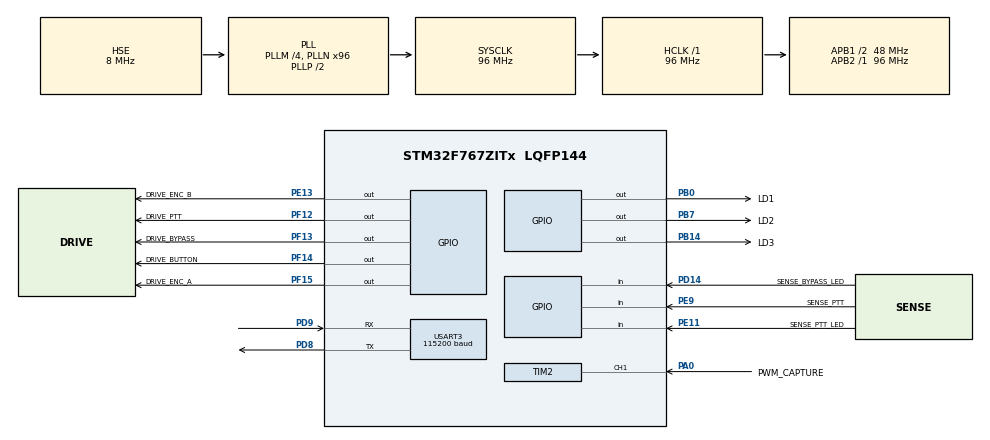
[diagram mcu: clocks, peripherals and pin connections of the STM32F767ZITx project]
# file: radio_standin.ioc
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IWDG.Prescaler=IWDG_PRESCALER_32
IWDG.Reload=1999
Mcu.Family=STM32F7
Mcu.Name=STM32F767ZITx
Mcu.Package=LQFP144
NVIC.PriorityGroup=NVIC_PRIORITYGROUP_4
NVIC.TIM2_IRQn=true\:1\:0\:false\:false\:true\:true\:true\:true
NVIC.USART3_IRQn=true\:2\:0\:false\:false\:true\:true\:true\:true
PA0/WKUP.GPIO_Label=PWM_CAPTURE
PA0/WKUP.Signal=S_TIM2_CH1_ETR
PA13.Signal=SYS_JTMS-SWDIO
PA14.Signal=SYS_JTCK-SWCLK
PB0.GPIO_Label=LD1
PB0.Signal=GPIO_Output
PB14.GPIO_Label=LD3
PB14.Signal=GPIO_Output
PB7.GPIO_Label=LD2
PB7.Signal=GPIO_Output
PD14.GPIO_Label=SENSE_BYPASS_LED
PD14.Signal=GPIO_Input
PD8.Mode=Asynchronous
PD8.Signal=USART3_TX
PD9.Mode=Asynchronous
PD9.Signal=USART3_RX
PE11.GPIO_Label=SENSE_PTT_LED
PE11.Signal=GPIO_Input
PE13.GPIO_Label=DRIVE_ENC_B
PE13.GPIO_ModeDefaultOutputPP=GPIO_MODE_OUTPUT_OD
PE13.PinState=GPIO_PIN_SET
PE13.Signal=GPIO_Output
PE9.GPIO_Label=SENSE_PTT
PE9.Signal=GPIO_Input
PF12.GPIO_Label=DRIVE_PTT
PF12.GPIO_ModeDefaultOutputPP=GPIO_MODE_OUTPUT_OD
PF12.PinState=GPIO_PIN_SET
PF12.Signal=GPIO_Output
PF13.GPIO_Label=DRIVE_BYPASS
PF13.GPIO_ModeDefaultOutputPP=GPIO_MODE_OUTPUT_OD
PF13.PinState=GPIO_PIN_SET
PF13.Signal=GPIO_Output
PF14.GPIO_Label=DRIVE_BUTTON
PF14.GPIO_ModeDefaultOutputPP=GPIO_MODE_OUTPUT_OD
PF14.PinState=GPIO_PIN_SET
PF14.Signal=GPIO_Output
PF15.GPIO_Label=DRIVE_ENC_A
PF15.GPIO_ModeDefaultOutputPP=GPIO_MODE_OUTPUT_OD
PF15.PinState=GPIO_PIN_SET
PF15.Signal=GPIO_Output
PH0/OSC_IN.Mode=HSE-External-Clock-Source
PH0/OSC_IN.Signal=RCC_OSC_IN
PH1/OSC_OUT.Mode=HSE-External-Clock-Source
PH1/OSC_OUT.Signal=RCC_OSC_OUT
ProjectManager.HeapSize=0x200
ProjectManager.StackSize=0x1000
ProjectManager.TargetToolchain=CMake
RCC.48MHZClocksFreq_Value=24000000
RCC.AHBFreq_Value=96000000
RCC.APB1CLKDivider=RCC_HCLK_DIV2
RCC.APB1Freq_Value=48000000
RCC.APB1TimFreq_Value=96000000
RCC.APB2Freq_Value=96000000
RCC.APB2TimFreq_Value=96000000
RCC.CortexFreq_Value=96000000
RCC.HCLKFreq_Value=96000000
RCC.HSE_VALUE=8000000
RCC.HSI_VALUE=16000000
RCC.LSE_VALUE=32768
RCC.PLLM=4
RCC.PLLMUL=RCC_PLL_MUL9
RCC.PLLN=96
RCC.PLLQ=4
RCC.PLLSourceVirtual=RCC_PLLSOURCE_HSE
RCC.PRESCALERUSB=RCC_USBCLKSOURCE_PLL_DIV1_5
RCC.SYSCLKFreq_VALUE=96000000
RCC.SYSCLKSource=RCC_SYSCLKSOURCE_PLLCLK
RCC.SYSCLKSourceVirtual=RCC_SYSCLKSOURCE_PLLCLK
RCC.USBFreq_Value=48000000
RCC.VCOOutputFreq_Value=192000000
SH.S_TIM2_CH1_ETR.0=TIM2_CH1,Input_Capture1_from_TI1
TIM2.Channel-Input_Capture1_from_TI1=TIM_CHANNEL_1
TIM2.ICPolarity_CH1=TIM_INPUTCHANNELPOLARITY_BOTHEDGE
TIM2.Period=4294967295
TIM2.Prescaler=95
USART3.BaudRate=115200
USART3.VirtualMode-Asynchronous=VM_ASYNC
VP_IWDG_VS_IWDG.Mode=IWDG_Activate
VP_TIM2_VS_ClockSourceINT.Mode=Internal
board=NUCLEO-F767ZI

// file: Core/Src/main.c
/* USER CODE BEGIN Header */
/**
  ******************************************************************************
  * @file           : main.c
  * @brief          : Main program body
  ******************************************************************************
  * @attention
  *
  * Copyright (c) 2026 STMicroelectronics.
  * All rights reserved.
  *
  * This software is licensed under terms that can be found in the LICENSE file
  * in the root directory of this software component.
  * If no LICENSE file comes with this software, it is provided AS-IS.
  *
  ******************************************************************************
  */
/* USER CODE END Header */
#include "main.h"
#include "iwdg.h"
#include "tim.h"
#include "usart.h"
#include "gpio.h"

/* USER CODE BEGIN Includes */
#include "standin.h"
/* USER CODE END Includes */

void SystemClock_Config(void);

int main(void)
{

  /* MCU Configuration--------------------------------------------------------*/

  /* Reset of all peripherals, Initializes the Flash interface and the Systick. */
  HAL_Init();

  /* Configure the system clock */
  SystemClock_Config();

  /* Initialize all configured peripherals */
  MX_GPIO_Init();
  MX_TIM2_Init();
  MX_USART3_UART_Init();
  MX_IWDG_Init();
  /* USER CODE BEGIN 2 */
  Standin_Init();
  /* USER CODE END 2 */

  /* Infinite loop */
  while (1)
  {

    /* USER CODE BEGIN 3 */
    Standin_Poll();
  }
  /* USER CODE END 3 */
}

void SystemClock_Config(void)
{
  RCC_OscInitTypeDef RCC_OscInitStruct = {0};
  RCC_ClkInitTypeDef RCC_ClkInitStruct = {0};

  /** Configure the main internal regulator output voltage
  */
  __HAL_RCC_PWR_CLK_ENABLE();
  __HAL_PWR_VOLTAGESCALING_CONFIG(PWR_REGULATOR_VOLTAGE_SCALE3);

  /** Initializes the RCC Oscillators according to the specified parameters
  * in the RCC_OscInitTypeDef structure.
  */
  RCC_OscInitStruct.OscillatorType = RCC_OSCILLATORTYPE_LSI|RCC_OSCILLATORTYPE_HSE;
  RCC_OscInitStruct.HSEState = RCC_HSE_BYPASS;
  RCC_OscInitStruct.LSIState = RCC_LSI_ON;
  RCC_OscInitStruct.PLL.PLLState = RCC_PLL_ON;
  RCC_OscInitStruct.PLL.PLLSource = RCC_PLLSOURCE_HSE;
  RCC_OscInitStruct.PLL.PLLM = 4;
  RCC_OscInitStruct.PLL.PLLN = 96;
  RCC_OscInitStruct.PLL.PLLP = RCC_PLLP_DIV2;
  RCC_OscInitStruct.PLL.PLLQ = 4;
  RCC_OscInitStruct.PLL.PLLR = 2;
  if (HAL_RCC_OscConfig(&RCC_OscInitStruct) != HAL_OK)
  {
    Error_Handler();
  }

  /** Activate the Over-Drive mode
  */
  if (HAL_PWREx_EnableOverDrive() != HAL_OK)
  {
    Error_Handler();
  }

  /** Initializes the CPU, AHB and APB buses clocks
  */
  RCC_ClkInitStruct.ClockType = RCC_CLOCKTYPE_HCLK|RCC_CLOCKTYPE_SYSCLK
                              |RCC_CLOCKTYPE_PCLK1|RCC_CLOCKTYPE_PCLK2;
  RCC_ClkInitStruct.SYSCLKSource = RCC_SYSCLKSOURCE_PLLCLK;
  RCC_ClkInitStruct.AHBCLKDivider = RCC_SYSCLK_DIV1;
  RCC_ClkInitStruct.APB1CLKDivider = RCC_HCLK_DIV2;
  RCC_ClkInitStruct.APB2CLKDivider = RCC_HCLK_DIV1;

  if (HAL_RCC_ClockConfig(&RCC_ClkInitStruct, FLASH_LATENCY_3) != HAL_OK)
  {
    Error_Handler();
  }
}

void Error_Handler(void)
{
  /* USER CODE BEGIN Error_Handler_Debug */
  /* User can add his own implementation to report the HAL error return state */
  Standin_Release();
  __disable_irq();
  while (1)
  {
  }
  /* USER CODE END Error_Handler_Debug */
}
